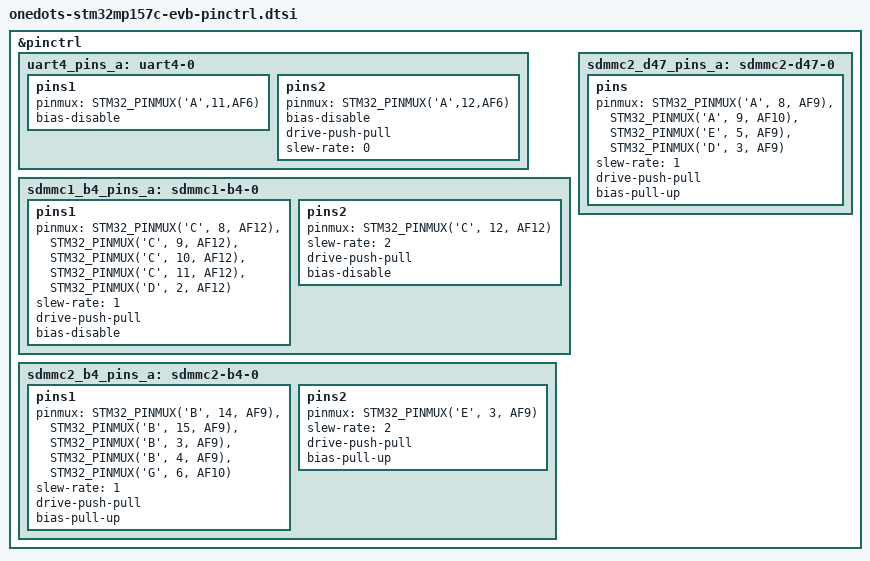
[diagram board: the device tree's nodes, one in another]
// SPDX-License-Identifier: (GPL-2.0+ OR BSD-3-Clause)
/*
 * Copyright (c) 2017-2023, STMicroelectronics - All Rights Reserved
 * Author: Ludovic Barre <ludovic.barre@st.com> for STMicroelectronics.
 */
#include <dt-bindings/pinctrl/stm32-pinfunc.h>

&pinctrl {
	uart4_pins_a: uart4-0 {
		pins1 {
			pinmux = <STM32_PINMUX('A',11,AF6)>;
			bias-disable;
		};
		pins2 {
			pinmux = <STM32_PINMUX('A',12,AF6)>;
			bias-disable;
			drive-push-pull;
			slew-rate = <0>;
		};
	};
	
		sdmmc1_b4_pins_a: sdmmc1-b4-0 {
		pins1 {
			pinmux = <STM32_PINMUX('C', 8, AF12)>, /* SDMMC1_D0 */
				 <STM32_PINMUX('C', 9, AF12)>, /* SDMMC1_D1 */
				 <STM32_PINMUX('C', 10, AF12)>, /* SDMMC1_D2 */
				 <STM32_PINMUX('C', 11, AF12)>, /* SDMMC1_D3 */
				 <STM32_PINMUX('D', 2, AF12)>; /* SDMMC1_CMD */
			slew-rate = <1>;
			drive-push-pull;
			bias-disable;
		};
		pins2 {
			pinmux = <STM32_PINMUX('C', 12, AF12)>; /* SDMMC1_CK */
			slew-rate = <2>;
			drive-push-pull;
			bias-disable;
		};
	};

	sdmmc2_b4_pins_a: sdmmc2-b4-0 {
		pins1 {
			pinmux = <STM32_PINMUX('B', 14, AF9)>, /* SDMMC2_D0 */
				 <STM32_PINMUX('B', 15, AF9)>, /* SDMMC2_D1 */
				 <STM32_PINMUX('B', 3, AF9)>, /* SDMMC2_D2 */
				 <STM32_PINMUX('B', 4, AF9)>, /* SDMMC2_D3 */
				 <STM32_PINMUX('G', 6, AF10)>; /* SDMMC2_CMD */
			slew-rate = <1>;
			drive-push-pull;
			bias-pull-up;
		};
		pins2 {
			pinmux = <STM32_PINMUX('E', 3, AF9)>; /* SDMMC2_CK */
			slew-rate = <2>;
			drive-push-pull;
			bias-pull-up;
		};
	};

	sdmmc2_d47_pins_a: sdmmc2-d47-0 {
		pins {
			pinmux = <STM32_PINMUX('A', 8, AF9)>, /* SDMMC2_D4 */
				 <STM32_PINMUX('A', 9, AF10)>, /* SDMMC2_D5 */
				 <STM32_PINMUX('E', 5, AF9)>, /* SDMMC2_D6 */
				 <STM32_PINMUX('D', 3, AF9)>; /* SDMMC2_D7 */
			slew-rate = <1>;
			drive-push-pull;
			bias-pull-up;
		};
	};


};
